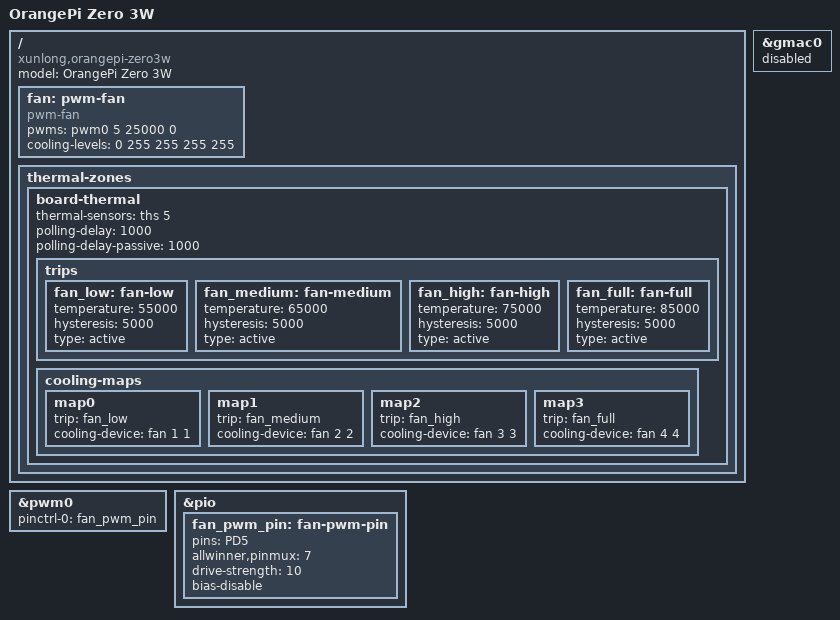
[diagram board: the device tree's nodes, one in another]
// SPDX-License-Identifier: (GPL-2.0-only OR MIT)
/*
 * Orange Pi Zero 3W.
 *
 * The same processor, power management chip, wireless module and Type-C
 * data port as on the Orange Pi Zero 4, on a smaller board that carries
 * no Ethernet PHY.
 */

#include "sun60i-a733-orangepi-zero4.dts"

/ {
	model = "OrangePi Zero 3W";
	compatible = "xunlong,orangepi-zero3w", "allwinner,sun60i-a733";

	/* PWM wiring from the pinned Orange Pi BSP. The stock kit fan is
	 * two-wire: the header switches its supply rail, and a chopped
	 * rail runs the motor only near the full duty. Collapse the
	 * vendor table to off/full until a four-wire fan is accepted. */
	fan: pwm-fan {
		compatible = "pwm-fan";
		pwms = <&pwm0 5 25000 0>;
		#cooling-cells = <2>;
		cooling-levels = <0 255 255 255 255>;
		/* DC1SW2 also powers microSD. Never switch it off here. */
	};

	thermal-zones {
		board-thermal {
			/* Local THS index 5 returns the hottest of all five sensors. */
			thermal-sensors = <&ths 5>;
			polling-delay = <1000>;
			polling-delay-passive = <1000>;
			trips {
				fan_low: fan-low {
					temperature = <55000>;
					hysteresis = <5000>;
					type = "active";
				};
				fan_medium: fan-medium {
					temperature = <65000>;
					hysteresis = <5000>;
					type = "active";
				};
				fan_high: fan-high {
					temperature = <75000>;
					hysteresis = <5000>;
					type = "active";
				};
				fan_full: fan-full {
					temperature = <85000>;
					hysteresis = <5000>;
					type = "active";
				};
			};
			cooling-maps {
				map0 {
					trip = <&fan_low>;
					cooling-device = <&fan 1 1>;
				};
				map1 {
					trip = <&fan_medium>;
					cooling-device = <&fan 2 2>;
				};
				map2 {
					trip = <&fan_high>;
					cooling-device = <&fan 3 3>;
				};
				map3 {
					trip = <&fan_full>;
					cooling-device = <&fan 4 4>;
				};
			};
		};
	};
};

/* Nothing is wired to the MAC: its pins are left to the pin header. */
&gmac0 {
	status = "disabled";
};

&pwm0 {
	pinctrl-names = "default";
	pinctrl-0 = <&fan_pwm_pin>;
	status = "okay";
};

&pio {
	fan_pwm_pin: fan-pwm-pin {
		pins = "PD5";
		allwinner,pinmux = <7>;
		drive-strength = <10>;
		bias-disable;
	};
};
